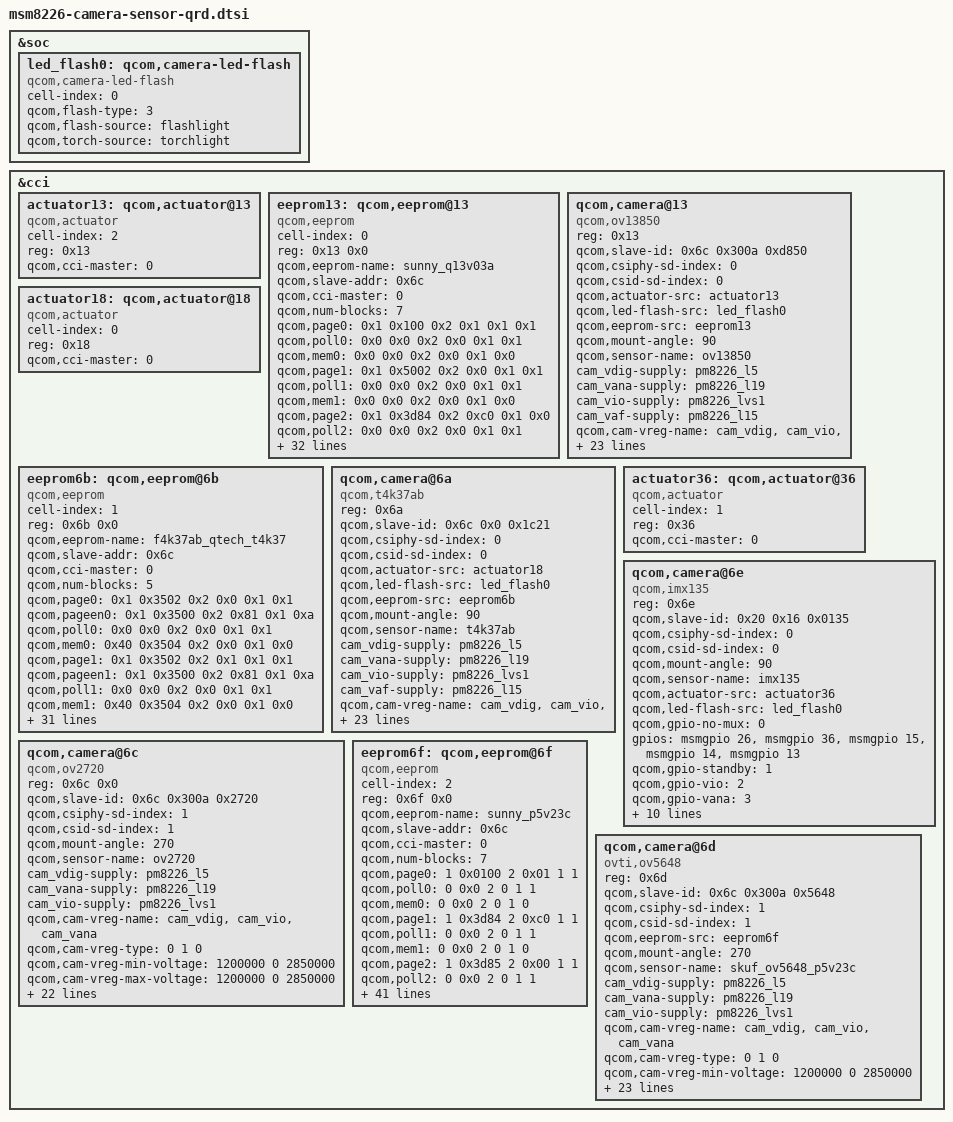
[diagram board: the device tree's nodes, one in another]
/*
 * Copyright (c) 2015, The Linux Foundation. All rights reserved.
 *
 * This program is free software; you can redistribute it and/or modify
 * it under the terms of the GNU General Public License version 2 and
 * only version 2 as published by the Free Software Foundation.
 *
 * This program is distributed in the hope that it will be useful,
 * but WITHOUT ANY WARRANTY; without even the implied warranty of
 * MERCHANTABILITY or FITNESS FOR A PARTICULAR PURPOSE.  See the
 * GNU General Public License for more details.
 */

&soc {

	led_flash0: qcom,camera-led-flash {
		cell-index = <0>;
		compatible = "qcom,camera-led-flash";
		qcom,flash-type = <3>;
		qcom,flash-source = <&flashlight>;
		qcom,torch-source = <&torchlight>;
	};
};

&cci {

	actuator13: qcom,actuator@13 {
		cell-index = <2>;
		reg = <0x13>;
		compatible = "qcom,actuator";
		qcom,cci-master = <0>;
	};

	eeprom13: qcom,eeprom@13 {
		cell-index = <0>;
		reg = <0x13 0x0>;
		qcom,eeprom-name = "sunny_q13v03a";
		compatible = "qcom,eeprom";
		qcom,slave-addr = <0x6c>;
		qcom,cci-master = <0>;
		qcom,num-blocks = <7>;
		qcom,page0 = <0x1 0x100 0x2 0x1 0x1 0x1>;
		qcom,poll0 = <0x0 0x0 0x2 0x0 0x1 0x1>;
		qcom,mem0 = <0x0 0x0 0x2 0x0 0x1 0x0>;
		qcom,page1 = <0x1 0x5002 0x2 0x0 0x1 0x1>;
		qcom,poll1 = <0x0 0x0 0x2 0x0 0x1 0x1>;
		qcom,mem1 = <0x0 0x0 0x2 0x0 0x1 0x0>;
		qcom,page2 = <0x1 0x3d84 0x2 0xc0 0x1 0x0>;
		qcom,poll2 = <0x0 0x0 0x2 0x0 0x1 0x1>;
		qcom,mem2 = <0x0 0x0 0x2 0x0 0x1 0x0>;
		qcom,page3 = <0x1 0x3d88 0x2 0x7220 0x2 0x0>;
		qcom,poll3 = <0x0 0x0 0x2 0x0 0x1 0x1>;
		qcom,mem3 = <0x0 0x0 0x2 0x0 0x1 0x0>;
		qcom,page4 = <0x1 0x3d8a 0x2 0x7369 0x2 0x0>;
		qcom,poll4 = <0x0 0x0 0x2 0x0 0x1 0x1>;
		qcom,mem4 = <0x0 0x0 0x2 0x0 0x1 0x0>;
		qcom,page5 = <0x1 0x3d81 0x2 0x1 0x1 0xf>;
		qcom,poll5 = <0x0 0x0 0x2 0x0 0x1 0x1>;
		qcom,mem5 = <0xe5 0x7220 0x2 0x0 0x1 0x0>;
		qcom,page6 = <0x1 0x5002 0x2 0x1 0x1 0x1>;
		qcom,poll6 = <0x0 0x0 0x2 0x0 0x1 0x1>;
		qcom,mem6 = <0x0 0x0 0x2 0x0 0x1 0x0>;

		qcom,gpio-no-mux = <0>;
		gpios = <&msmgpio 26 0>,
			<&msmgpio 36 0>,
			<&msmgpio 15 0>,
			<&msmgpio 14 0>,
			<&msmgpio 13 0>;
		qcom,gpio-standby = <1>;
		qcom,gpio-vio = <2>;
		qcom,gpio-vana = <3>;
		qcom,gpio-vdig = <4>;
		qcom,gpio-req-tbl-num = <0 1 2 3 4>;
		qcom,gpio-req-tbl-flags = <1 0 0 0 0>;
		qcom,gpio-req-tbl-label = "CAMIF_MCLK", "CAM_STANDBY", "CAM_VIO", "CAM_VANA", "CAM_VDIG";
		qcom,cam-power-seq-type = "sensor_gpio", "sensor_gpio", "sensor_gpio", "sensor_gpio", "sensor_clk";
		qcom,cam-power-seq-val = "sensor_gpio_vio", "sensor_gpio_vana", "sensor_gpio_vdig", "sensor_gpio_standby", "sensor_cam_mclk";
		qcom,cam-power-seq-cfg-val = <1 1 1 1 24000000>;
		qcom,cam-power-seq-delay = <5 5 10 10 20>;
	};

	qcom,camera@13 {
		compatible = "qcom,ov13850";
		reg = <0x13>;
		qcom,slave-id = <0x6c 0x300a 0xd850>;
		qcom,csiphy-sd-index = <0>;
		qcom,csid-sd-index = <0>;
		qcom,actuator-src = <&actuator13>;
		qcom,led-flash-src = <&led_flash0>;
		qcom,eeprom-src = <&eeprom13>;
		qcom,mount-angle = <90>;
		qcom,sensor-name = "ov13850";
		
		cam_vdig-supply = <&pm8226_l5>;
		cam_vana-supply = <&pm8226_l19>;
		cam_vio-supply = <&pm8226_lvs1>;
		cam_vaf-supply = <&pm8226_l15>;
		qcom,cam-vreg-name = "cam_vdig", "cam_vio", "cam_vana", "cam_vaf";
		qcom,cam-vreg-type = <0 1 0 0>;
		qcom,cam-vreg-min-voltage = <1200000 0 2850000 2800000>;
		qcom,cam-vreg-max-voltage = <1200000 0 2850000 2800000>;
		qcom,cam-vreg-op-mode = <200000 0 80000 100000>;
		
		qcom,gpio-no-mux = <0>;
		gpios = <&msmgpio 26 0>,
			<&msmgpio 36 0>,
			<&msmgpio 15 0>,
			<&msmgpio 14 0>,
			<&msmgpio 13 0>;
		qcom,gpio-standby = <0x1>;
		qcom,gpio-vio = <0x2>;
		qcom,gpio-vana = <0x3>;
		qcom,gpio-vdig = <0x4>;
		qcom,gpio-req-tbl-num = <0 1 2 3 4>;
		qcom,gpio-req-tbl-flags = <1 0 0 0 0>;
		qcom,gpio-req-tbl-label = "CAMIF_MCLK", "CAM_STANDBY", "CAM_VIO", "CAM_VANA", "CAM_VDIG";
		qcom,csi-lane-assign = <0x4320>;
		qcom,csi-lane-mask = <0x1f>;
		qcom,sensor-position = <0>;
		qcom,sensor-mode = <1>;
		qcom,cci-master = <0>;
	};

	actuator18: qcom,actuator@18 {
		cell-index = <0>;
		reg = <0x18>;
		compatible = "qcom,actuator";
		qcom,cci-master = <0>;
	};

	eeprom6b: qcom,eeprom@6b{
		cell-index = <1>;
		reg = <0x6b 0x0>;
		qcom,eeprom-name = "f4k37ab_qtech_t4k37";
		compatible = "qcom,eeprom";
		qcom,slave-addr = <0x6c>;
		qcom,cci-master = <0>;
		qcom,num-blocks = <5>;
		qcom,page0 = <0x1 0x3502 0x2 0x0 0x1 0x1>;
		qcom,pageen0 = <0x1 0x3500 0x2 0x81 0x1 0xa>;
		qcom,poll0 = <0x0 0x0 0x2 0x0 0x1 0x1>;
		qcom,mem0 = <0x40 0x3504 0x2 0x0 0x1 0x0>;
		qcom,page1 = <0x1 0x3502 0x2 0x1 0x1 0x1>;
		qcom,pageen1 = <0x1 0x3500 0x2 0x81 0x1 0xa>;
		qcom,poll1 = <0x0 0x0 0x2 0x0 0x1 0x1>;
		qcom,mem1 = <0x40 0x3504 0x2 0x0 0x1 0x0>;
		qcom,page2 = <0x1 0x3502 0x2 0x2 0x1 0x1>;
		qcom,pageen2 = <0x1 0x3500 0x2 0x81 0x1 0xa>;
		qcom,poll2 = <0x0 0x0 0x2 0x0 0x1 0x1>;
		qcom,mem2 = <0x40 0x3504 0x2 0x0 0x1 0x0>;
		qcom,page3 = <0x1 0x3502 0x2 0x3 0x1 0x1>;
		qcom,pageen3 = <0x1 0x3500 0x2 0x81 0x1 0xa>;
		qcom,poll3 = <0x0 0x0 0x2 0x0 0x1 0x1>;
		qcom,mem3 = <0x40 0x3504 0x2 0x0 0x1 0x0>;
		qcom,page4 = <0x1 0x3502 0x2 0x4 0x1 0x1>;
		qcom,pageen4 = <0x1 0x3500 0x2 0x81 0x1 0xa>;
		qcom,poll4 = <0x0 0x0 0x2 0x0 0x1 0x1>;
		qcom,mem4 = <0x40 0x3504 0x2 0x0 0x1 0x0>;

		qcom,gpio-no-mux = <0>;
		gpios = <&msmgpio 26 0>,
			<&msmgpio 36 0>,
			<&msmgpio 15 0>,
			<&msmgpio 14 0>,
			<&msmgpio 13 0>;
		qcom,gpio-standby = <1>;
		qcom,gpio-vio = <2>;
		qcom,gpio-vana = <3>;
		qcom,gpio-vdig = <4>;
		qcom,gpio-req-tbl-num = <0 1 2 3 4>;
		qcom,gpio-req-tbl-flags = <1 0 0 0 0>;
		qcom,gpio-req-tbl-label = "CAMIF_MCLK", "CAM_STANDBY", "CAM_VIO", "CAM_VANA", "CAM_VDIG";
		qcom,cam-power-seq-type = "sensor_gpio", "sensor_gpio", "sensor_gpio", "sensor_gpio", "sensor_clk";
		qcom,cam-power-seq-val = "sensor_gpio_vio", "sensor_gpio_vana", "sensor_gpio_vdig", "sensor_gpio_standby", "sensor_cam_mclk";
		qcom,cam-power-seq-cfg-val = <1 1 1 1 24000000>;
		qcom,cam-power-seq-delay = <5 5 10 10 20>;
	};

	qcom,camera@6a {
		compatible = "qcom,t4k37ab";
		reg = <0x6a>;
		qcom,slave-id = <0x6c 0x0 0x1c21>;
		qcom,csiphy-sd-index = <0>;
		qcom,csid-sd-index = <0>;
		qcom,actuator-src = <&actuator18>;
		qcom,led-flash-src = <&led_flash0>;
		qcom,eeprom-src = <&eeprom6b>;
		qcom,mount-angle = <90>;
		qcom,sensor-name = "t4k37ab";
		
		cam_vdig-supply = <&pm8226_l5>;
		cam_vana-supply = <&pm8226_l19>;
		cam_vio-supply = <&pm8226_lvs1>;
		cam_vaf-supply = <&pm8226_l15>;
		qcom,cam-vreg-name = "cam_vdig", "cam_vio", "cam_vana", "cam_vaf";
		qcom,cam-vreg-type = <0 1 0 0>;
		qcom,cam-vreg-min-voltage = <1200000 0 2850000 2800000>;
		qcom,cam-vreg-max-voltage = <1200000 0 2850000 2800000>;
		qcom,cam-vreg-op-mode = <120000 0 0 80000 100000>;
		
		qcom,gpio-no-mux = <0>;
		gpios = <&msmgpio 26 0>,
			<&msmgpio 36 0>,
			<&msmgpio 15 0>,
			<&msmgpio 14 0>,
			<&msmgpio 13 0>;
		qcom,gpio-standby = <1>;
		qcom,gpio-vio = <2>;
		qcom,gpio-vana = <3>;
		qcom,gpio-vdig = <4>;
		qcom,gpio-req-tbl-num = <0 1 2 3 4>;
		qcom,gpio-req-tbl-flags = <1 0 0 0 0>;
		qcom,gpio-req-tbl-label = "CAMIF_MCLK", "CAM_STANDBY", "CAM_VIO", "CAM_VANA", "CAM_VDIG";
		qcom,csi-lane-assign = <0x4320>;
		qcom,csi-lane-mask = <0x1f>;
		qcom,sensor-position = <0>;
		qcom,sensor-mode = <1>;
		qcom,cci-master = <0>;
	};

	/* ------ SONY camera block -------- */

	actuator36: qcom,actuator@36 {
		cell-index = <1>;
		reg = <0x36>;
		compatible = "qcom,actuator";
		qcom,cci-master = <0>;
	};

	qcom,camera@6e {
		compatible = "qcom,imx135";
		reg = <0x6e>;
		qcom,slave-id = <0x20 0x16 0x0135>;
		qcom,csiphy-sd-index = <0>;
		qcom,csid-sd-index = <0>;
		qcom,mount-angle = <90>;
		qcom,sensor-name = "imx135";
		qcom,actuator-src = <&actuator36>;
		qcom,led-flash-src = <&led_flash0>;
		
		qcom,gpio-no-mux = <0>;
		gpios = <&msmgpio 26 0>,
			<&msmgpio 36 0>,
			<&msmgpio 15 0>,
			<&msmgpio 14 0>,
			<&msmgpio 13 0>;
		qcom,gpio-standby = <1>;
		qcom,gpio-vio = <2>;
		qcom,gpio-vana = <3>;
		qcom,gpio-vdig = <4>;
		qcom,gpio-req-tbl-num = <0 1 2 3 4>;
		qcom,gpio-req-tbl-flags = <1 0 0 0 0>;
		qcom,gpio-req-tbl-label = "CAMIF_MCLK", "CAM_STANDBY", "CAM_VIO", "CAM_VANA", "CAM_VDIG";
		qcom,csi-lane-assign = <0x4320>;
		qcom,csi-lane-mask = <0x1f>;
		qcom,sensor-position = <0>;
		qcom,sensor-mode = <1>;
		qcom,cci-master = <0>;
		status = "ok";
	};	

	/* ------ FRONTAL camera block -------- */

	qcom,camera@6c {
		compatible = "qcom,ov2720";
		reg = <0x6c 0x0>;
		qcom,slave-id = <0x6c 0x300a 0x2720>;
		qcom,csiphy-sd-index = <1>;
		qcom,csid-sd-index = <1>;
		qcom,mount-angle = <270>;
		qcom,sensor-name = "ov2720";
		
		cam_vdig-supply = <&pm8226_l5>;
		cam_vana-supply = <&pm8226_l19>;
		cam_vio-supply = <&pm8226_lvs1>;
		qcom,cam-vreg-name = "cam_vdig", "cam_vio", "cam_vana";
		qcom,cam-vreg-type = <0 1 0>;
		qcom,cam-vreg-min-voltage = <1200000 0 2850000>;
		qcom,cam-vreg-max-voltage = <1200000 0 2850000>;
		qcom,cam-vreg-op-mode = <200000 0 80000>;
		
		qcom,gpio-no-mux = <0>;
		gpios = <&msmgpio 26 0>,
				<&msmgpio 28 0>,
				<&msmgpio 35 0>,
				<&msmgpio 0 0>,
				<&msmgpio 1 0>,
				<&msmgpio 22 0>;
		qcom,gpio-reset = <1>;
		qcom,gpio-standby = <2>;
		qcom,gpio-vio = <3>;
		qcom,gpio-vana = <4>;
		qcom,gpio-vdig = <5>;
		qcom,gpio-req-tbl-num = <0 1 2 3 4 5>;
		qcom,gpio-req-tbl-flags = <1 0 0 0 0 0>;
		qcom,gpio-req-tbl-label = "CAMIF_MCLK", "CAM_RESET", "CAM_STANDBY", "CAM_VIO", "CAM_VANA", "CAM_VDIG";
		qcom,gpio-set-tbl-num = <1 1>;
		qcom,gpio-set-tbl-flags = <0 2>;
		qcom,gpio-set-tbl-delay = <1000 4000>;
		qcom,csi-lane-assign = <0x4320>;
		qcom,csi-lane-mask = <0x3>;
		qcom,sensor-position = <1>;
		qcom,sensor-mode = <1>;
		qcom,cci-master = <0>;
		status = "ok";
	};
	
	eeprom6f: qcom,eeprom@6f{
		cell-index = <2>;
		reg = <0x6f 0x0>;
		qcom,eeprom-name = "sunny_p5v23c";
		compatible = "qcom,eeprom";
		qcom,slave-addr = <0x6c>;
		qcom,cci-master = <0>;
		qcom,num-blocks = <7>;

		qcom,page0 = <1 0x0100 2 0x01 1 1>;
		qcom,poll0 = <0 0x0 2 0 1 1>;
		qcom,mem0 = <0 0x0 2 0 1 0>;

		qcom,page1 = <1 0x3d84 2 0xc0 1 1>;
		qcom,poll1 = <0 0x0 2 0 1 1>;
		qcom,mem1 = <0 0x0 2 0 1 0>;
		qcom,page2 = <1 0x3d85 2 0x00 1 1>;
		qcom,poll2 = <0 0x0 2 0 1 1>;
		qcom,mem2 = <0 0x0 2 0 1 0>;
		qcom,page3 = <1 0x3d86 2 0x0f 1 1>;
		qcom,pageen3 = <1 0x3d81 2 0x01 1 10>;
		qcom,poll3 = <0 0x0 2 0 1 1>;
		qcom,mem3 = <16 0x3d00 2 0 1 0>;

		qcom,page4 = <1 0x3d84 2 0xc0 1 1>;
		qcom,poll4 = <0 0x0 2 0 1 1>;
		qcom,mem4 = <0 0x0 2 0 1 0>;
		qcom,page5 = <1 0x3d85 2 0x10 1 1>;
		qcom,poll5 = <0 0x0 2 0 1 1>;
		qcom,mem5 = <0 0x0 2 0 1 0>;
		qcom,page6 = <1 0x3d86 2 0x1f 1 1>;
		qcom,pageen6 = <1 0x3d81 2 0x01 1 10>;
		qcom,poll6 = <0 0x0 2 0 1 1>;
		qcom,mem6 = <16 0x3d00 2 0 1 0>;

		cam_vio-supply = <&pm8226_lvs1>;
		cam_vana-supply = <&pm8226_l19>;
		qcom,cam-vreg-name = "cam_vdig", "cam_vio", "cam_vana";
		qcom,cam-vreg-type = <0 1 0>;
		qcom,cam-vreg-min-voltage = <1200000 0 2850000>;
		qcom,cam-vreg-max-voltage = <1200000 0 2850000>;
		qcom,cam-vreg-op-mode = <200000 0 80000>;
		
		qcom,gpio-no-mux = <0>;
		gpios = <&msmgpio 26 0>, 
			<&msmgpio 28 0>, 
			<&msmgpio 35 0>, 
			<&msmgpio 22 0>;
		qcom,gpio-reset = <1>;
		qcom,gpio-standby = <2>;
		qcom,gpio-vdig = <3>;
		qcom,gpio-req-tbl-num = <0 1 2 3>;
		qcom,gpio-req-tbl-flags = <1 0 0 0>;
		qcom,gpio-req-tbl-label = "CAMIF_MCLK", "CAM_RESET", "CAM_STANDBY", "CAM_VDIG";
		qcom,cam-power-seq-type = "sensor_vreg", "sensor_vreg", "sensor_gpio", "sensor_gpio", "sensor_gpio", "sensor_clk";
		qcom,cam-power-seq-val = "cam_vio", "cam_vana", "sensor_gpio_vdig", "sensor_gpio_reset", "sensor_gpio_standby", "sensor_cam_mclk";
		qcom,cam-power-seq-cfg-val = <1 1 1 1 1 24000000>;
		qcom,cam-power-seq-delay = <1 1 10 10 10 5>;
	};

	qcom,camera@6d {
		compatible = "ovti,ov5648";
		reg = <0x6d>;
		qcom,slave-id = <0x6c 0x300a 0x5648>;
		qcom,csiphy-sd-index = <1>;
		qcom,csid-sd-index = <1>;
		qcom,eeprom-src = <&eeprom6f>;
		qcom,mount-angle = <270>;
		qcom,sensor-name = "skuf_ov5648_p5v23c";
		
		cam_vdig-supply = <&pm8226_l5>;
		cam_vana-supply = <&pm8226_l19>;
		cam_vio-supply = <&pm8226_lvs1>;
		qcom,cam-vreg-name = "cam_vdig", "cam_vio", "cam_vana";
		qcom,cam-vreg-type = <0 1 0>;
		qcom,cam-vreg-min-voltage = <1200000 0 2850000>;
		qcom,cam-vreg-max-voltage = <1200000 0 2850000>;
		qcom,cam-vreg-op-mode = <200000 0 80000>;
		
		qcom,gpio-no-mux = <0>;
		gpios = <&msmgpio 26 0>,
				<&msmgpio 28 0>,
				<&msmgpio 35 0>,
				<&msmgpio 0 0>,
				<&msmgpio 1 0>,
				<&msmgpio 22 0>;
		qcom,gpio-reset = <1>;
		qcom,gpio-standby = <2>;
		qcom,gpio-vio = <3>;
		qcom,gpio-vana = <4>;
		qcom,gpio-vdig = <5>;
		qcom,gpio-req-tbl-num = <0 1 2 3 4 5>;
		qcom,gpio-req-tbl-flags = <1 0 0 0 0 0>;
		qcom,gpio-req-tbl-label = "CAMIF_MCLK", "CAM_RESET", "CAM_STANDBY", "CAM_VIO", "CAM_VANA", "CAM_VDIG";
		qcom,gpio-set-tbl-num = <1 1>;
		qcom,gpio-set-tbl-flags = <0 2>;
		qcom,gpio-set-tbl-delay = <1000 4000>;
		qcom,csi-lane-assign = <0x4320>;
		qcom,csi-lane-mask = <0x3>;
		qcom,sensor-position = <1>;
		qcom,sensor-mode = <1>;
		qcom,cci-master = <0>;
		status = "ok";
	};

};
